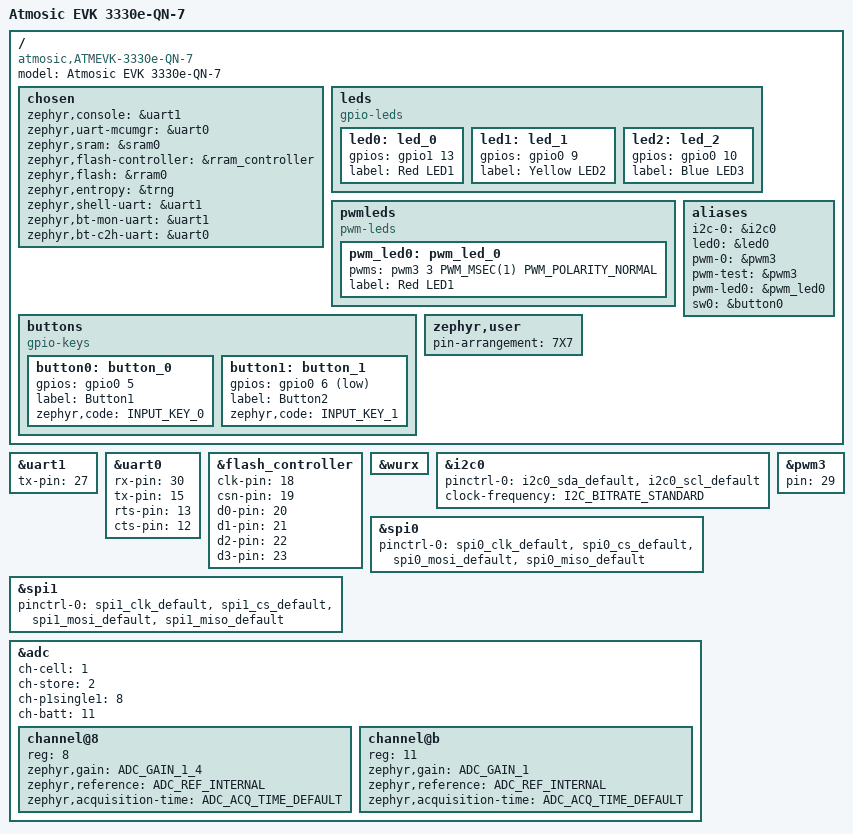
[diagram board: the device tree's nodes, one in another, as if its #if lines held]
/*
 * Copyright (c) 2021-2026 Atmosic
 *
 * SPDX-License-Identifier: LicenseRef-Atmosic
 */

/dts-v1/;
#include <arm/atmosic/ATM33xx.dtsi>
#include <dt-bindings/gpio/gpio.h>
#include <zephyr/dt-bindings/input/input-event-codes.h>
#include "pinctrl.dtsi"

/ {
	model = "Atmosic EVK 3330e-QN-7";
	compatible = "atmosic,ATMEVK-3330e-QN-7";

	chosen {
		zephyr,console = &uart1;
		zephyr,uart-mcumgr = &uart0;
		zephyr,sram = &sram0;
		zephyr,flash-controller = &rram_controller;
		zephyr,flash = &rram0;
		zephyr,entropy = &trng;
#ifdef ATM_DTS_USER_APP
		zephyr,shell-uart = &uart1;
		zephyr,bt-mon-uart = &uart1;
		zephyr,bt-c2h-uart = &uart0;
#endif
	};

#ifdef ATM_DTS_USER_APP
	leds {
		compatible = "gpio-leds";
		led0: led_0 {
			gpios = <&gpio1 13 GPIO_ACTIVE_HIGH>;
			label = "Red LED1";
		};
		led1: led_1 {
			gpios = <&gpio0 9 GPIO_ACTIVE_HIGH>;
			label = "Yellow LED2";
		};
		led2: led_2 {
			gpios = <&gpio0 10 GPIO_ACTIVE_HIGH>;
			label = "Blue LED3";
		};
	};

        pwmleds {
                compatible = "pwm-leds";
                pwm_led0: pwm_led_0 {
                        pwms = <&pwm3 3 PWM_MSEC(1) PWM_POLARITY_NORMAL>;
			label = "Red LED1";
                };
        };

	buttons {
		compatible = "gpio-keys";
		button0: button_0 {
			gpios = <&gpio0 5 GPIO_ACTIVE_HIGH>;
			label = "Button1";
			zephyr,code = <INPUT_KEY_0>;
		};
		button1: button_1 {
			gpios = <&gpio0 6 GPIO_ACTIVE_LOW>;
			label = "Button2";
			zephyr,code = <INPUT_KEY_1>;
		};
	};

	/* These aliases are provided for compatibility with samples */
	aliases {
		i2c-0 = &i2c0;
		led0 = &led0;
		pwm-0 = &pwm3;
		pwm-test = &pwm3;
		pwm-led0 = &pwm_led0;
		sw0 = &button0;
	};
#endif

	zephyr,user {
		pin-arrangement = "7X7";
	};
};

&uart1 {
	tx-pin = <27>;
};

&uart0 {
	rx-pin = <30>;
	tx-pin = <15>;
	rts-pin = <13>;
	cts-pin = <12>;
};

#if FLASH_SIZE
&flash_controller {
	clk-pin = <18>;
	csn-pin = <19>;
	d0-pin = <20>;
	d1-pin = <21>;
	d2-pin = <22>;
	d3-pin = <23>;
};
#endif

&wurx {
	status = "okay";
};

#ifdef ATM_DTS_USER_APP
&i2c0 {
	pinctrl-0 = <&i2c0_sda_default &i2c0_scl_default>;
	pinctrl-names = "default";
	clock-frequency = <I2C_BITRATE_STANDARD>;
};

&pwm3 {
	pin = <29>;
	status = "okay";
};

&spi0 {
	pinctrl-0 = <&spi0_clk_default &spi0_cs_default &spi0_mosi_default &spi0_miso_default>;
	pinctrl-names = "default";
};

&spi1 {
	pinctrl-0 = <&spi1_clk_default &spi1_cs_default &spi1_mosi_default &spi1_miso_default>;
	pinctrl-names = "default";
};

&adc {
	ch-cell = <1>;
	ch-store = <2>;
	ch-p1single1 = <8>;
	ch-batt = <11>;

	#address-cells = <1>;
	#size-cells = <0>;

	channel@8 {
		reg = <8>;
		zephyr,gain = "ADC_GAIN_1_4";
		zephyr,reference = "ADC_REF_INTERNAL";
		zephyr,acquisition-time = <ADC_ACQ_TIME_DEFAULT>;
	};

	/* VBATLI channel */
	channel@b {
		reg = <11>;
		zephyr,gain = "ADC_GAIN_1";
		zephyr,reference = "ADC_REF_INTERNAL";
		zephyr,acquisition-time = <ADC_ACQ_TIME_DEFAULT>;
	};
};

arduino_i2c: &i2c0 {};
#endif
